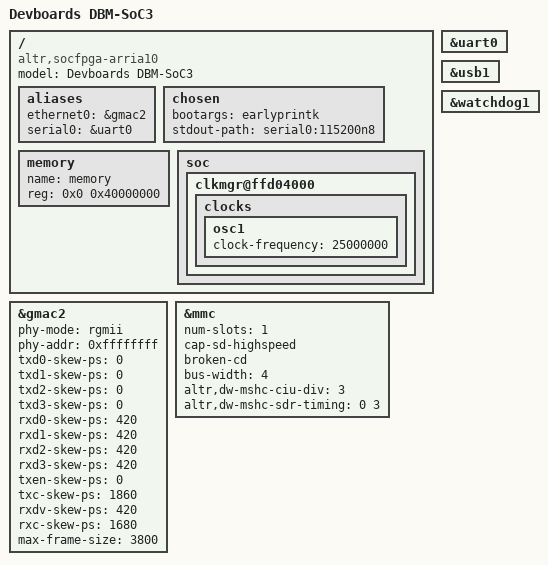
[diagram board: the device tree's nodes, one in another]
/*
 * Copyright (C) 2015 Altera Corporation. All rights reserved.
 *
 * This program is free software; you can redistribute it and/or modify
 * it under the terms and conditions of the GNU General Public License,
 * version 2, as published by the Free Software Foundation.
 *
 * This program is distributed in the hope it will be useful, but WITHOUT
 * ANY WARRANTY; without even the implied warranty of MERCHANTABILITY or
 * FITNESS FOR A PARTICULAR PURPOSE.  See the GNU General Public License for
 * more details.
 *
 * You should have received a copy of the GNU General Public License along with
 * this program.  If not, see <http://www.gnu.org/licenses/>.
 */

/dts-v1/;
#include "socfpga_arria10.dtsi"

/ {
	model = "Devboards DBM-SoC3";
	compatible = "altr,socfpga-arria10", "altr,socfpga";

	aliases {
		ethernet0 = &gmac2;
		serial0 = &uart0;
	};

	chosen {
		bootargs = "earlyprintk";
		stdout-path = "serial0:115200n8";
	};

	memory {
		name = "memory";
		device_type = "memory";
		reg = <0x0 0x40000000>; /* 1GB */
	};

	soc {
		clkmgr@ffd04000 {
			clocks {
				osc1 {
					clock-frequency = <25000000>;
				};
			};
		};
	};
};

&gmac2 {
	phy-mode = "rgmii";
	phy-addr = <0xffffffff>; /* probe for phy addr */

	/*
	 * These skews assume the user's FPGA design is adding 600ps of delay
	 * for TX_CLK on Arria 10.
	 *
	 * All skews are offset since hardware skew values for the ksz9031
	 * range from a negative skew to a positive skew.
	 * See the micrel-ksz90x1.txt Documentation file for details.
	 */
	txd0-skew-ps = <0>; /* -420ps */
	txd1-skew-ps = <0>; /* -420ps */
	txd2-skew-ps = <0>; /* -420ps */
	txd3-skew-ps = <0>; /* -420ps */
	rxd0-skew-ps = <420>; /* 0ps */
	rxd1-skew-ps = <420>; /* 0ps */
	rxd2-skew-ps = <420>; /* 0ps */
	rxd3-skew-ps = <420>; /* 0ps */
	txen-skew-ps = <0>; /* -420ps */
	txc-skew-ps = <1860>; /* 960ps */
	rxdv-skew-ps = <420>; /* 0ps */
	rxc-skew-ps = <1680>; /* 780ps */
	max-frame-size = <3800>;
	status = "okay";
};

&uart0 {
	status = "okay";
};

&usb1 {
	status = "okay";
};

&watchdog1 {
	status = "okay";
};

&mmc {
        status = "okay";
        num-slots = <1>;
        cap-sd-highspeed;
        broken-cd;
        bus-width = <4>;
        altr,dw-mshc-ciu-div = <3>;
        altr,dw-mshc-sdr-timing = <0 3>;
};
